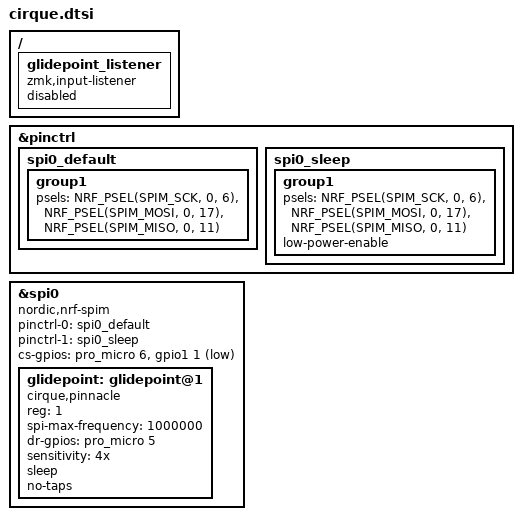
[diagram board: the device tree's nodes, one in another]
/*
 * Copyright (c) 2022 The ZMK Contributors
 *
 * SPDX-License-Identifier: MIT
 */
/ {
    glidepoint_listener: glidepoint_listener {
        compatible = "zmk,input-listener";
        status = "disabled";
    };
};

&pinctrl {
    spi0_default: spi0_default {
        group1 {
            psels = <NRF_PSEL(SPIM_SCK, 0, 6)>,
                    <NRF_PSEL(SPIM_MOSI, 0, 17)>,
                    <NRF_PSEL(SPIM_MISO, 0, 11)>;
        };
    };
    spi0_sleep: spi0_sleep {
        group1 {
            psels = <NRF_PSEL(SPIM_SCK, 0, 6)>,
                    <NRF_PSEL(SPIM_MOSI, 0, 17)>,
                    <NRF_PSEL(SPIM_MISO, 0, 11)>;
            low-power-enable;
        };
    };
};

nice_view_spi: &spi0 {
    compatible = "nordic,nrf-spim";
    pinctrl-0 = <&spi0_default>;
    pinctrl-1 = <&spi0_sleep>;
    pinctrl-names = "default", "sleep";
    cs-gpios = <&pro_micro 6 GPIO_ACTIVE_HIGH>, <&gpio1 1 GPIO_ACTIVE_LOW>;
    // cs-gpios = <&pro_micro 14 GPIO_ACTIVE_LOW>;
    glidepoint: glidepoint@1 {
        compatible = "cirque,pinnacle";
        reg = <1>;
        spi-max-frequency = <1000000>;
        status = "okay";
        dr-gpios = <&pro_micro 5 (GPIO_ACTIVE_HIGH)>;

        sensitivity = "4x";
        sleep;
        no-taps;
    };

};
